# Comparator_E_1 register map
Vendor: Texas Instruments
Peripheral module from a debugger description file (folder msp430).
Registers are 16-bit, read-write, reset 0x0 unless marked. A register's access mark holds for its fields unless they carry their own. Offsets are as the file gives them; lines under a group give offsets from that group; [hi:lo] are bit positions; {n}, {i} and the like mark numbered series; 'fields as' and 'values as' point back to an identical list; <NAME> marks a mode.

## Comparator_E
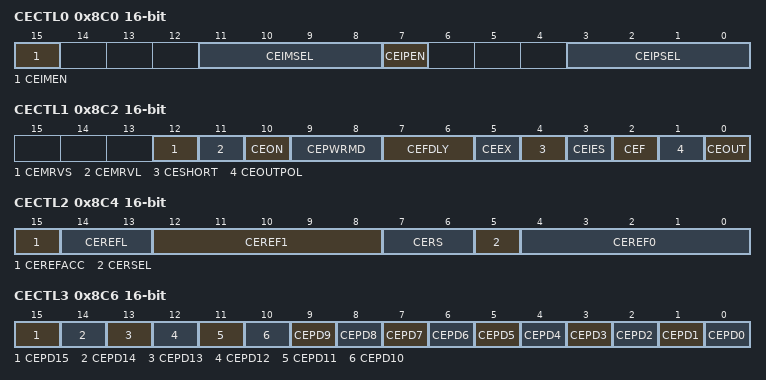
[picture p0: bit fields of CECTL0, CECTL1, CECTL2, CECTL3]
0x8C0 CECTL0 — Comparator E Control Register 0
  [15] CEIMEN — Comp. E Neg. Channel Input Enable
  [11:8] CEIMSEL — Comp. E Neg. Channel Input Select 0
    {v}=Comp. E V- Terminal Input Select: Channel {v} (v=0..7); {v}=Comp. E V- terminal Input Select: Channel {v} (v=8..15)
  [7] CEIPEN — Comp. E Pos. Channel Input Enable
  [3:0] CEIPSEL — Comp. E Pos. Channel Input Select 0
    {v}=Comp. E V+ terminal Input Select: Channel {v} (v=0..15)
0x8C2 CECTL1 — Comparator E Control Register 1
  [12] CEMRVS — Comp. E Output selects between VREF0 or VREF1
  [11] CEMRVL — Comp. E CEMRV Level
  [10] CEON — Comp. E enable
  [9:8] CEPWRMD — Comp. E Power mode Bit 0
    {v}=Comp. E Power mode {v} (v=0..3)
  [7:6] CEFDLY — Comp. E Filter delay Bit 0
    0=Comp. E Filter delay 0 : 450ns; 1=Comp. E Filter delay 1 : 900ns; 2=Comp. E Filter delay 2 : 1800ns; 3=Comp. E Filter delay 3 : 3600ns
  [5] CEEX — Comp. E Exchange Inputs
  [4] CESHORT — Comp. E Input Short
  [3] CEIES — Comp. E Interrupt Edge Select
  [2] CEF — Comp. E Enable Output Filter
  [1] CEOUTPOL — Comp. E Output Polarity
  [0] CEOUT — Comp. E Output
0x8C4 CECTL2 — Comparator E Control Register 2
  [15] CEREFACC — Comp. E Reference Accuracy
  [14:13] CEREFL — Comp. E Reference voltage level Bit : 0
    0=Comp. E Reference voltage level 0 : None; 1=Comp. E Reference voltage level 1 : 1.2V; 2=Comp. E Reference voltage level 2 : 2.0V; 3=Comp. E Reference voltage level 3 : 2.5V
  [12:8] CEREF1 — Comp. E Reference 1 Resistor Select Bit : 0
    {v}=Comp. E Int. Ref.1 Select {v} : {v+1}/32 (v=0..7); {v}=Comp. E Int. Ref.1 Select {v-8} : {v+1}/32 (v=8..15); {v}=Comp. E Int. Ref.1 Select {v-16} : {v+1}/32 (v=16..23); {v}=Comp. E Int. Ref.1 Select {v-24} : {v+1}/32 (v=24..31)
  [7:6] CERS — Comp. E Reference Source Bit : 0
    0=Comp. E Reference Source 0 : Off; 1=Comp. E Reference Source 1 : Vcc; 2=Comp. E Reference Source 2 : Shared Ref.; 3=Comp. E Reference Source 3 : Shared Ref. / Off
  [5] CERSEL — Comp. E Reference select
  [4:0] CEREF0 — Comp. E Reference 0 Resistor Select Bit : 0
    {v}=Comp. E Int. Ref.0 Select {v} : {v+1}/32 (v=0..7); {v}=Comp. E Int. Ref.0 Select {v-8} : {v+1}/32 (v=8..15); {v}=Comp. E Int. Ref.0 Select {v-16} : {v+1}/32 (v=16..23); {v}=Comp. E Int. Ref.0 Select {v-24} : {v+1}/32 (v=24..31)
0x8C6 CECTL3 — Comparator E Control Register 3
  [15] CEPD15 — Comp. E Disable Input Buffer of Port Register .15
  [14] CEPD14 — Comp. E Disable Input Buffer of Port Register .14
  [13] CEPD13 — Comp. E Disable Input Buffer of Port Register .13
  [12] CEPD12 — Comp. E Disable Input Buffer of Port Register .12
  [11] CEPD11 — Comp. E Disable Input Buffer of Port Register .11
  [10] CEPD10 — Comp. E Disable Input Buffer of Port Register .10
  [9] CEPD9 — Comp. E Disable Input Buffer of Port Register .9
  [8] CEPD8 — Comp. E Disable Input Buffer of Port Register .8
  [7] CEPD7 — Comp. E Disable Input Buffer of Port Register .7
  [6] CEPD6 — Comp. E Disable Input Buffer of Port Register .6
  [5] CEPD5 — Comp. E Disable Input Buffer of Port Register .5
  [4] CEPD4 — Comp. E Disable Input Buffer of Port Register .4
  [3] CEPD3 — Comp. E Disable Input Buffer of Port Register .3
  [2] CEPD2 — Comp. E Disable Input Buffer of Port Register .2
  [1] CEPD1 — Comp. E Disable Input Buffer of Port Register .1
  [0] CEPD0 — Comp. E Disable Input Buffer of Port Register .0
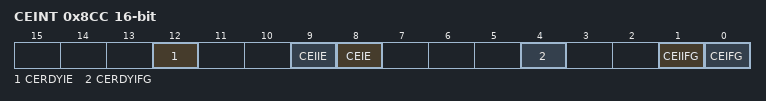
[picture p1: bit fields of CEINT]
0x8CC CEINT — Comparator E Interrupt Register
  [12] CERDYIE — Comp. E Comparator_E ready interrupt enable
  [9] CEIIE — Comp. E Interrupt Enable Inverted Polarity
  [8] CEIE — Comp. E Interrupt Enable
  [4] CERDYIFG — Comp. E Comparator_E ready interrupt flag
  [1] CEIIFG — Comp. E Interrupt Flag Inverted Polarity
  [0] CEIFG — Comp. E Interrupt Flag
0x8CE CEIV access not given reset not defined — Comparator E Interrupt Vector Word
